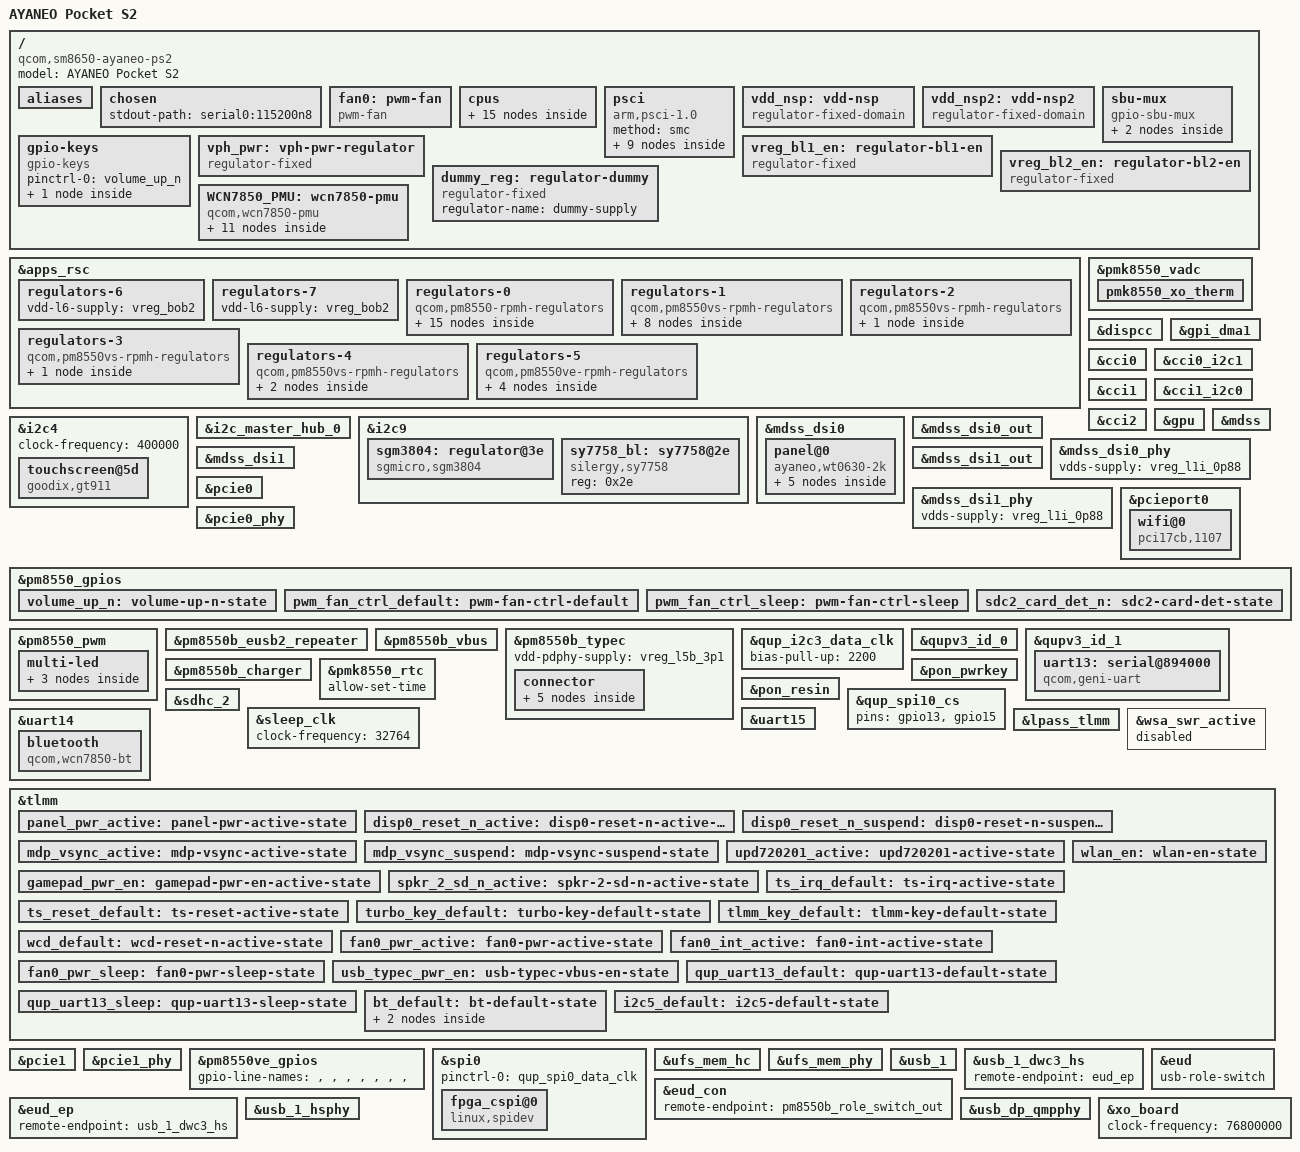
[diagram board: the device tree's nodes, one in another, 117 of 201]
/dts-v1/;

#include <dt-bindings/leds/common.h>
#include <dt-bindings/regulator/qcom,rpmh-regulator.h>
#include <dt-bindings/phy/phy.h>
#include "dt-bindings/usb/pd.h"
#include "sm8650.dtsi"
#include "pm8010.dtsi"
#include "pm8550.dtsi"
#include "pm8550b.dtsi"
#include "pm8550vs.dtsi"
#define PMK8550VE_SID 8
#include "pm8550ve.dtsi"
#include "pmk8550.dtsi"
#include "sm8650-el2.dtsi"

/ {
	model = "AYANEO Pocket S2";
	compatible = "qcom,sm8650-ayaneo-ps2", "qcom,sm8650";

	aliases {
		serial0 = &uart15;
		serial1 = &uart14;
		hsuart0 = &uart13;
	};

	chosen {
		stdout-path = "serial0:115200n8";
	};	

	fan0: pwm-fan {
		status = "okay";
		compatible = "pwm-fan";
		#cooling-cells = <2>;
		interrupt-parent = <&tlmm>;
		interrupts = <14 IRQ_TYPE_EDGE_FALLING>;
		pinctrl-names = "default", "sleep";
		pinctrl-0 = <&fan0_pwr_active>, <&pwm_fan_ctrl_default>, <&fan0_int_active>;
		pinctrl-1 = <&fan0_pwr_sleep>;
		pwms = <&pm8550_pwm 3 50000>;
		cooling-levels = <0 16 32 45 60 80 105 130 155 180 205 230 255>;
	};
	
	cpus {

		CPU0: cpu@0 {
			power-domains = <&CPU_PD0>;
			power-domain-names = "psci";
		};

		CPU1: cpu@100 {
			power-domains = <&CPU_PD1>;
			power-domain-names = "psci";
		};

		CPU2: cpu@200 {
			power-domains = <&CPU_PD2>;
			power-domain-names = "psci";
		};

		CPU3: cpu@300 {
			power-domains = <&CPU_PD3>;
			power-domain-names = "psci";
		};

		CPU4: cpu@400 {
			power-domains = <&CPU_PD4>;
			power-domain-names = "psci";
		};

		CPU5: cpu@500 {
			power-domains = <&CPU_PD5>;
			power-domain-names = "psci";
		};

		CPU6: cpu@600 {
			power-domains = <&CPU_PD6>;
			power-domain-names = "psci";
		};

		CPU7: cpu@700 {
			power-domains = <&CPU_PD7>;
			power-domain-names = "psci";
		};

		idle-states {
			entry-method = "psci";

			SILVER_CPU_SLEEP_0: cpu-sleep-0-0 {
				compatible = "arm,idle-state";
				idle-state-name = "silver-rail-power-collapse";
				arm,psci-suspend-param = <0x40000004>;
				entry-latency-us = <550>;
				exit-latency-us = <750>;
				min-residency-us = <6700>;
				local-timer-stop;
			};

			GOLD_CPU_SLEEP_0: cpu-sleep-1-0 {
				compatible = "arm,idle-state";
				idle-state-name = "gold-rail-power-collapse";
				arm,psci-suspend-param = <0x40000004>;
				entry-latency-us = <600>;
				exit-latency-us = <1300>;
				min-residency-us = <8136>;
				local-timer-stop;
			};

			GOLD_PLUS_CPU_SLEEP_0: cpu-sleep-2-0 {
				compatible = "arm,idle-state";
				idle-state-name = "gold-plus-rail-power-collapse";
				arm,psci-suspend-param = <0x40000004>;
				entry-latency-us = <500>;
				exit-latency-us = <1350>;
				min-residency-us = <7480>;
				local-timer-stop;
			};
		};

		domain-idle-states {
			CLUSTER_SLEEP_0: cluster-sleep-0 {
				compatible = "domain-idle-state";
				arm,psci-suspend-param = <0x41000044>;
				entry-latency-us = <750>;
				exit-latency-us = <2350>;
				min-residency-us = <9144>;
			};

			CLUSTER_SLEEP_1: cluster-sleep-1 {
				compatible = "domain-idle-state";
				arm,psci-suspend-param = <0x4100c344>;
				entry-latency-us = <2800>;
				exit-latency-us = <4400>;
				min-residency-us = <10150>;
			};
		};
	};

	psci {
		compatible = "arm,psci-1.0";
		method = "smc";

		CPU_PD0: power-domain-cpu0 {
			#power-domain-cells = <0>;
			power-domains = <&CLUSTER_PD>;
			domain-idle-states = <&SILVER_CPU_SLEEP_0>;
		};

		CPU_PD1: power-domain-cpu1 {
			#power-domain-cells = <0>;
			power-domains = <&CLUSTER_PD>;
			domain-idle-states = <&SILVER_CPU_SLEEP_0>;
		};

		CPU_PD2: power-domain-cpu2 {
			#power-domain-cells = <0>;
			power-domains = <&CLUSTER_PD>;
			domain-idle-states = <&SILVER_CPU_SLEEP_0>;
		};

		CPU_PD3: power-domain-cpu3 {
			#power-domain-cells = <0>;
			power-domains = <&CLUSTER_PD>;
			domain-idle-states = <&GOLD_CPU_SLEEP_0>;
		};

		CPU_PD4: power-domain-cpu4 {
			#power-domain-cells = <0>;
			power-domains = <&CLUSTER_PD>;
			domain-idle-states = <&GOLD_CPU_SLEEP_0>;
		};

		CPU_PD5: power-domain-cpu5 {
			#power-domain-cells = <0>;
			power-domains = <&CLUSTER_PD>;
			domain-idle-states = <&GOLD_CPU_SLEEP_0>;
		};

		CPU_PD6: power-domain-cpu6 {
			#power-domain-cells = <0>;
			power-domains = <&CLUSTER_PD>;
			domain-idle-states = <&GOLD_CPU_SLEEP_0>;
		};

		CPU_PD7: power-domain-cpu7 {
			#power-domain-cells = <0>;
			power-domains = <&CLUSTER_PD>;
			domain-idle-states = <&GOLD_PLUS_CPU_SLEEP_0>;
		};

		CLUSTER_PD: power-domain-cluster {
			#power-domain-cells = <0>;
			domain-idle-states = <&CLUSTER_SLEEP_0>,
					     <&CLUSTER_SLEEP_1>;
		};
	};

	vdd_nsp: vdd-nsp {
		compatible = "regulator-fixed-domain";
		power-domains = <&rpmhpd RPMHPD_NSP>;
		required-opps = <&rpmhpd_opp_nom>;
		regulator-name = "NSP";
		regulator-always-on;
	};

	vdd_nsp2: vdd-nsp2 {
		compatible = "regulator-fixed-domain";
		power-domains = <&rpmhpd RPMHPD_NSP2>;
		required-opps = <&rpmhpd_opp_nom>;
		regulator-name = "NSP2";
		regulator-always-on;
	};

	sbu-mux {
		compatible = "gpio-sbu-mux";

		enable-gpios = <&tlmm 86 GPIO_ACTIVE_LOW>;
		select-gpios = <&tlmm 82 GPIO_ACTIVE_HIGH>;

		mode-switch;
		orientation-switch;

		port {
			sbu_mux_in: endpoint {
				remote-endpoint = <&tcpm_sbu_out>;
			};
		};

		// XXX: needs VREG_L05B_3P1, VREG_BOB2
	};

	gpio-keys {
		compatible = "gpio-keys";

		pinctrl-0 = <&volume_up_n>;
		pinctrl-names = "default";

		key-volume-up {
			label = "Volume Up";
			linux,code = <KEY_VOLUMEUP>;
			gpios = <&pm8550_gpios 6 GPIO_ACTIVE_LOW>;
			debounce-interval = <15>;
			linux,can-disable;
			//wakeup-source;
		};
	};

	vph_pwr: vph-pwr-regulator {
		compatible = "regulator-fixed";

		regulator-name = "vph_pwr";
		regulator-min-microvolt = <3700000>;
		regulator-max-microvolt = <3700000>;

		regulator-always-on;
		regulator-boot-on;
	};

	vreg_bl1_en: regulator-bl1-en {
		compatible = "regulator-fixed";
		regulator-name = "vreg_bl1_en";
		gpio = <&tlmm 163 GPIO_ACTIVE_HIGH>;
		enable-active-high;
		regulator-always-on;
	};

	vreg_bl2_en: regulator-bl2-en {
		compatible = "regulator-fixed";
		regulator-name = "vreg_bl2_en";
		gpio = <&tlmm 164 GPIO_ACTIVE_HIGH>;
		enable-active-high;
		regulator-always-on;
	};

	dummy_reg: regulator-dummy {
		compatible = "regulator-fixed";
		regulator-name = "dummy-supply";
	};

	WCN7850_PMU: wcn7850-pmu {
		compatible = "qcom,wcn7850-pmu";

		pinctrl-names = "default";
		pinctrl-0 = <&wlan_en>, <&bt_default>;

		wlan-enable-gpios = <&tlmm 16 GPIO_ACTIVE_HIGH>;
		bt-enable-gpios = <&tlmm 17 GPIO_ACTIVE_HIGH>;

		vdd-supply = <&vreg_s4i_0p85>;
		vddio-supply = <&vreg_l15b_1p8>;
		vddio1p2-supply = <&vreg_l3c_1p2>;
		vddaon-supply = <&vreg_s2c_0p8>;
		vdddig-supply = <&vreg_s3c_0p9>;
		vddrfa1p2-supply = <&vreg_s1c_1p2>;
		vddrfa1p8-supply = <&vreg_s6c_1p8>;

		clocks = <&rpmhcc RPMH_RF_CLK1>;

		regulators {
			vreg_pmu_rfa_cmn: ldo0 {
				regulator-name = "vreg_pmu_rfa_cmn";
			};

			vreg_pmu_aon_0p59: ldo1 {
				regulator-name = "vreg_pmu_aon_0p59";
			};

			vreg_pmu_wlcx_0p8: ldo2 {
				regulator-name = "vreg_pmu_wlcx_0p8";
			};

			vreg_pmu_wlmx_0p85: ldo3 {
				regulator-name = "vreg_pmu_wlmx_0p85";
			};

			vreg_pmu_btcmx_0p85: ldo4 {
				regulator-name = "vreg_pmu_btcmx_0p85";
			};

			vreg_pmu_rfa_0p8: ldo5 {
				regulator-name = "vreg_pmu_rfa_0p8";
			};

			vreg_pmu_rfa_1p2: ldo6 {
				regulator-name = "vreg_pmu_rfa_1p2";
			};

			vreg_pmu_rfa_1p8: ldo7 {
				regulator-name = "vreg_pmu_rfa_1p8";
			};

			vreg_pmu_pcie_0p9: ldo8 {
				regulator-name = "vreg_pmu_pcie_0p9";
			};

			vreg_pmu_pcie_1p8: ldo9 {
				regulator-name = "vreg_pmu_pcie_1p8";
			};
		};
	};


};


&apps_rsc {
    regulators-6 {
        vdd-l6-supply = <&vreg_bob2>;
    };
    regulators-7 {
        vdd-l6-supply = <&vreg_bob2>;
    };
};

&pmk8550_vadc {
	// NOTE TODO REVISIT - There is some chance to lower interrupt usage slightly if these are converted to thermal zones and qcom,adc-tm-type is set appropriately..

	// NOTE Setting qcom,adc-tm-type errors out driver and blocks all channels with obscure error. Need Thermal Zone setup to match.
	pmk8550_xo_therm {
		reg = <PMK8550_ADC5_GEN3_AMUX_THM1_XO_THERM_100K_PU(0)>;
		label = "pmk8550_xo_therm";
		qcom,ratiometric;
		qcom,hw-settle-time = <200>;
		qcom,pre-scaling = <1 1>;
	};



};

&apps_rsc {
	regulators-0 {
		compatible = "qcom,pm8550-rpmh-regulators";

		vdd-bob1-supply = <&vph_pwr>;
		vdd-bob2-supply = <&vph_pwr>;
		vdd-l1-l4-l10-supply = <&vreg_s6c_1p8>;
		vdd-l2-l13-l14-supply = <&vreg_bob1>;
		vdd-l3-supply = <&vreg_s1c_1p2>;
		vdd-l5-l16-supply = <&vreg_bob1>;
		vdd-l6-l7-supply = <&vreg_bob1>;
		vdd-l8-l9-supply = <&vreg_bob1>;
		vdd-l11-supply = <&vreg_s1c_1p2>;
		vdd-l12-supply = <&vreg_s6c_1p8>;
		vdd-l15-supply = <&vreg_s6c_1p8>;
		vdd-l17-supply = <&vreg_bob2>;

		qcom,pmic-id = "b";

		vreg_bob1: bob1 {
			regulator-name = "vreg_bob1";
			regulator-min-microvolt = <3296000>; // note: min is 3008000, init is 3296000
			regulator-max-microvolt = <3960000>;
			regulator-initial-mode = <RPMH_REGULATOR_MODE_HPM>;
		};

		vreg_bob2: bob2 {
			regulator-name = "vreg_bob2";
			regulator-min-microvolt = <2720000>; // note: min is 2704000, init is 2720000
			regulator-max-microvolt = <3008000>;
			regulator-initial-mode = <RPMH_REGULATOR_MODE_HPM>;

			regulator-always-on; // XXX USB HS, SBU MUX
		};

		vreg_l2b_3p0: ldo2 {
			regulator-name = "vreg_l2b_3p0";
			regulator-min-microvolt = <3008000>;
			regulator-max-microvolt = <3008000>;
			regulator-initial-mode = <RPMH_REGULATOR_MODE_HPM>;
			regulator-allow-set-load;
			regulator-allowed-modes = <RPMH_REGULATOR_MODE_LPM
						   RPMH_REGULATOR_MODE_HPM>;
		};

		vreg_l5b_3p1: ldo5 {
			regulator-name = "vreg_l5b_3p1";
			regulator-min-microvolt = <3104000>;
			regulator-max-microvolt = <3104000>;
			regulator-initial-mode = <RPMH_REGULATOR_MODE_HPM>;
			regulator-allow-set-load;
			regulator-allowed-modes = <RPMH_REGULATOR_MODE_LPM
						   RPMH_REGULATOR_MODE_HPM>;
			regulator-always-on; // XXX SBU MUX
		};

		vreg_l6b_1p8: ldo6 {
			regulator-name = "vreg_l6b_1p8";
			regulator-min-microvolt = <1800000>;
			regulator-max-microvolt = <3008000>;
			regulator-initial-mode = <RPMH_REGULATOR_MODE_HPM>;
			regulator-allow-set-load;
			regulator-allowed-modes = <RPMH_REGULATOR_MODE_LPM
						   RPMH_REGULATOR_MODE_HPM>;
		};

		vreg_l7b_1p8: ldo7 {
			regulator-name = "vreg_l7b_1p8";
			regulator-min-microvolt = <1800000>;
			regulator-max-microvolt = <3008000>;
			regulator-initial-mode = <RPMH_REGULATOR_MODE_HPM>;
		};
		
		vreg_l8b_1p8: ldo8 {
			regulator-name = "vreg_l8b_1p8";
			regulator-min-microvolt = <1800000>;
			regulator-max-microvolt = <3008000>;
			regulator-initial-mode = <RPMH_REGULATOR_MODE_HPM>;
			regulator-allow-set-load;
			regulator-allowed-modes = <RPMH_REGULATOR_MODE_LPM
						   RPMH_REGULATOR_MODE_HPM>;
		};

		vreg_l9b_2p9: ldo9 {
			regulator-name = "vreg_l9b_2p9";
			regulator-min-microvolt = <2960000>;
			regulator-max-microvolt = <3008000>;
			regulator-initial-mode = <RPMH_REGULATOR_MODE_HPM>;
			regulator-allow-set-load;
			regulator-allowed-modes = <RPMH_REGULATOR_MODE_LPM
						   RPMH_REGULATOR_MODE_HPM>;
		};


		vreg_l11b_1p2: ldo11 {
			regulator-name = "vreg_l11b_1p2";
			regulator-min-microvolt = <1200000>;
			regulator-max-microvolt = <1504000>;
			regulator-initial-mode = <RPMH_REGULATOR_MODE_HPM>;
			regulator-allow-set-load;
			regulator-allowed-modes = <RPMH_REGULATOR_MODE_LPM
						   RPMH_REGULATOR_MODE_HPM>;
		};

		vreg_l12b_1p8: ldo12 {
			regulator-name = "vreg_l12b_1p8";
			regulator-min-microvolt = <1800000>;
			regulator-max-microvolt = <1800000>;
			regulator-initial-mode = <RPMH_REGULATOR_MODE_HPM>;
			regulator-allow-set-load;
			regulator-allowed-modes = <RPMH_REGULATOR_MODE_LPM
						   RPMH_REGULATOR_MODE_HPM>;
		};

		vreg_l13b_3p0: ldo13 {
			regulator-name = "vreg_l13b_3p0";
			regulator-min-microvolt = <3000000>;
			regulator-max-microvolt = <3000000>;
			regulator-initial-mode = <RPMH_REGULATOR_MODE_HPM>;
			regulator-allow-set-load;
			regulator-allowed-modes = <RPMH_REGULATOR_MODE_LPM
						   RPMH_REGULATOR_MODE_HPM>;
		};
	
		vreg_l14b_3p2: ldo14 {
			regulator-name = "vreg_l14b_3p2";
			regulator-min-microvolt = <3200000>;
			regulator-max-microvolt = <3200000>;
			regulator-initial-mode = <RPMH_REGULATOR_MODE_HPM>;
			regulator-allow-set-load;
			regulator-allowed-modes = <RPMH_REGULATOR_MODE_LPM
						   RPMH_REGULATOR_MODE_HPM>;
		};
	
		vreg_l15b_1p8: ldo15 {
			regulator-name = "vreg_l15b_1p8";
			regulator-min-microvolt = <1800000>;
			regulator-max-microvolt = <1800000>;
			regulator-initial-mode = <RPMH_REGULATOR_MODE_HPM>;
			regulator-allow-set-load;
			regulator-allowed-modes = <RPMH_REGULATOR_MODE_LPM
						   RPMH_REGULATOR_MODE_HPM>;
		};

		vreg_l16b_2p8: ldo16 {
			regulator-name = "vreg_l16b_2p8";
			regulator-min-microvolt = <2800000>;
			regulator-max-microvolt = <2800000>;
			regulator-initial-mode = <RPMH_REGULATOR_MODE_HPM>;
			regulator-allow-set-load;
			regulator-allowed-modes = <RPMH_REGULATOR_MODE_LPM
						   RPMH_REGULATOR_MODE_HPM>;
		};
		
		vreg_l17b_2p5: ldo17 {
			regulator-name = "vreg_l17b_2p5";
			regulator-min-microvolt = <2504000>;
			regulator-max-microvolt = <2504000>;
			regulator-initial-mode = <RPMH_REGULATOR_MODE_HPM>;
			regulator-allow-set-load;
			regulator-allowed-modes = <RPMH_REGULATOR_MODE_LPM
						   RPMH_REGULATOR_MODE_HPM>;
		};
	};

	regulators-1 {
		compatible = "qcom,pm8550vs-rpmh-regulators";

		vdd-l1-supply = <&vreg_s1c_1p2>;
		vdd-l2-supply = <&vreg_s1c_1p2>;
		vdd-l3-supply = <&vreg_s1c_1p2>;
		vdd-s1-supply = <&vph_pwr>;
		vdd-s2-supply = <&vph_pwr>;
		vdd-s3-supply = <&vph_pwr>;
		vdd-s4-supply = <&vph_pwr>;
		vdd-s5-supply = <&vph_pwr>;
		vdd-s6-supply = <&vph_pwr>;

		qcom,pmic-id = "c";

		vreg_s1c_1p2: smps1 {
			regulator-name = "vreg_s1c_1p2";
			regulator-min-microvolt = <1224000>;
			regulator-max-microvolt = <1348000>;
			// init 1256000
			regulator-initial-mode = <RPMH_REGULATOR_MODE_HPM>;

			regulator-always-on; // USB, UFS?
		};

		vreg_s2c_0p8: smps2 {
			regulator-name = "vreg_s2c_0p8";
			regulator-min-microvolt = <852000>;
			regulator-max-microvolt = <1036000>;
			// init 852000
			regulator-initial-mode = <RPMH_REGULATOR_MODE_HPM>;
		};

		vreg_s3c_0p9: smps3 {
			regulator-name = "vreg_s3c_0p9";
			regulator-min-microvolt = <904000>;
			regulator-max-microvolt = <1064000>;
			// init 976000
			regulator-initial-mode = <RPMH_REGULATOR_MODE_HPM>;
		};

		vreg_s4c_1p2: smps4 {
			regulator-name = "vreg_s4c_1p2";
			regulator-min-microvolt = <1200000>;
			regulator-max-microvolt = <1280000>;
			// init 1224000
			regulator-initial-mode = <RPMH_REGULATOR_MODE_HPM>;
		};

		vreg_s5c_0p7: smps5 {
			regulator-name = "vreg_s5c_0p7";
			regulator-min-microvolt = <752000>;
			regulator-max-microvolt = <900000>;
			// init 752000
			regulator-initial-mode = <RPMH_REGULATOR_MODE_HPM>;
		};

		vreg_s6c_1p8: smps6 {
			regulator-name = "vreg_s6c_1p8";
			regulator-min-microvolt = <1856000>;
			regulator-max-microvolt = <2000000>;
			// init 1856000
			regulator-initial-mode = <RPMH_REGULATOR_MODE_HPM>;
		};

		vreg_l1c_1p2: ldo1 {
			regulator-name = "vreg_l1c_1p2";
			regulator-min-microvolt = <1200000>; // note: min 1100000
			regulator-max-microvolt = <1200000>;
			regulator-initial-mode = <RPMH_REGULATOR_MODE_HPM>;
			regulator-allow-set-load;
			regulator-allowed-modes = <RPMH_REGULATOR_MODE_LPM
						   RPMH_REGULATOR_MODE_HPM>;
		};

		vreg_l3c_1p2: ldo3 {
			regulator-name = "vreg_l3c_1p2";
			regulator-min-microvolt = <1200000>;
			regulator-max-microvolt = <1200000>;
			regulator-initial-mode = <RPMH_REGULATOR_MODE_HPM>;
			regulator-allow-set-load;
			regulator-allowed-modes = <RPMH_REGULATOR_MODE_LPM
						   RPMH_REGULATOR_MODE_HPM>;
		};
	};

	regulators-2 {
		compatible = "qcom,pm8550vs-rpmh-regulators";
		qcom,pmic-id = "d";

		vdd-l1-supply = <&vreg_s3c_0p9>;

		vreg_l1d_0p9: ldo1 {
			regulator-name = "vreg_l1d_0p9";
			regulator-min-microvolt = <912000>; // note: min 880000
			regulator-max-microvolt = <920000>;
			regulator-initial-mode = <RPMH_REGULATOR_MODE_HPM>;
			regulator-allow-set-load;
			regulator-allowed-modes = <RPMH_REGULATOR_MODE_LPM
						   RPMH_REGULATOR_MODE_HPM>;
		};
	};

	regulators-3 {
		compatible = "qcom,pm8550vs-rpmh-regulators";

		vdd-l3-supply = <&vreg_s3c_0p9>;

		qcom,pmic-id = "e";

		vreg_l3e_0p9: ldo3 {
			regulator-name = "vreg_l3e_0p9";
			regulator-min-microvolt = <880000>;
			regulator-max-microvolt = <920000>;
			regulator-initial-mode = <RPMH_REGULATOR_MODE_HPM>;
			regulator-allow-set-load;
			regulator-allowed-modes = <RPMH_REGULATOR_MODE_LPM
						   RPMH_REGULATOR_MODE_HPM>;
		};
	};

	regulators-4 {
		compatible = "qcom,pm8550vs-rpmh-regulators";

		vdd-l1-supply = <&vreg_s3c_0p9>;
		vdd-l3-supply = <&vreg_s3c_0p9>;

		qcom,pmic-id = "g";

		vreg_l1g_0p91: ldo1 {
			regulator-name = "vreg_l1g_0p91";
			regulator-min-microvolt = <912000>;
			regulator-max-microvolt = <920000>;
			regulator-initial-mode = <RPMH_REGULATOR_MODE_HPM>;
			regulator-allow-set-load;
			regulator-allowed-modes = <RPMH_REGULATOR_MODE_LPM
						   RPMH_REGULATOR_MODE_HPM>;
		};

		vreg_l3g_0p91: ldo3 {
			regulator-name = "vreg_l3g_0p91";
			regulator-min-microvolt = <880000>;
			regulator-max-microvolt = <912000>;
			regulator-initial-mode = <RPMH_REGULATOR_MODE_HPM>;
			regulator-allow-set-load;
			regulator-allowed-modes = <RPMH_REGULATOR_MODE_LPM
						   RPMH_REGULATOR_MODE_HPM>;
		};
	};
	
	regulators-5 {
		compatible = "qcom,pm8550ve-rpmh-regulators";

		vdd-l1-supply = <&vreg_s3c_0p9>;
		vdd-l2-supply = <&vreg_s3c_0p9>;
		vdd-l3-supply = <&vreg_s1c_1p2>;
		vdd-s4-supply = <&vph_pwr>;

		qcom,pmic-id = "i";

		vreg_s4i_0p85: smps4 {
			regulator-name = "vreg_s4i_0p85";
			regulator-min-microvolt = <852000>;
			regulator-max-microvolt = <1004000>;
			// init 852000
			regulator-initial-mode = <RPMH_REGULATOR_MODE_HPM>;
		};

		vreg_l1i_0p88: ldo1 {
			regulator-name = "vreg_l1i_0p88";
			regulator-min-microvolt = <880000>;
			regulator-max-microvolt = <912000>;
			regulator-initial-mode = <RPMH_REGULATOR_MODE_HPM>;
			regulator-allow-set-load;
			regulator-allowed-modes = <RPMH_REGULATOR_MODE_LPM
						   RPMH_REGULATOR_MODE_HPM>;
		};

		vreg_l2i_0p88: ldo2 {
			regulator-name = "vreg_l2i_0p88";
			regulator-min-microvolt = <880000>;
			regulator-max-microvolt = <912000>;
			regulator-initial-mode = <RPMH_REGULATOR_MODE_HPM>;
			regulator-allow-set-load;
			regulator-allowed-modes = <RPMH_REGULATOR_MODE_LPM
						   RPMH_REGULATOR_MODE_HPM>;
		};

		vreg_l3i_1p2: ldo3 {
			regulator-name = "vreg_l3i_0p91";
			regulator-min-microvolt = <1200000>;
			regulator-max-microvolt = <1200000>;
			regulator-initial-mode = <RPMH_REGULATOR_MODE_HPM>;
			regulator-allow-set-load;
			regulator-allowed-modes = <RPMH_REGULATOR_MODE_LPM
						   RPMH_REGULATOR_MODE_HPM>;
		};
	};

};


&dispcc {
	status = "okay";
};

&gpi_dma1 {
	status = "okay";
};



&cci0 {
	status = "okay";
};



&cci0_i2c1 {

};

&cci1 {
	pinctrl-0 = <&cci1_0_default>;
	pinctrl-1 = <&cci1_0_sleep>;
	status = "okay";
};

&cci1_i2c0 {

};

&cci2 {
	status = "okay";
};


&i2c4 {
	status = "okay";
	clock-frequency = <400000>;

	touchscreen@5d {
		reg = <0x5d>;
		status = "okay";
		compatible = "goodix,gt911";

		interrupt-parent = <&tlmm>;
		interrupts = <162 IRQ_TYPE_EDGE_FALLING>;

		reset-gpios = <&tlmm 161 GPIO_ACTIVE_HIGH>;
		VDDIO-supply = <&vreg_l14b_3p2>;
		AVDD28-supply = <&vreg_l14b_3p2>;

		touchscreen-size-x = <1440>;
		touchscreen-size-y = <2560>;

		pinctrl-names = "default";
		pinctrl-0 = <&ts_reset_default>, <&ts_irq_default>, <&usb_typec_pwr_en>;
	};
};

&gpu {
	status = "okay";
};

// Master Hub required for Hub 7 and 8
&i2c_master_hub_0 {
	status = "okay";
};

&mdss {
	status = "okay";
};


&i2c9 {
	status = "okay";

	/* Screen power */
	sgm3804: regulator@3e {
		compatible = "sgmicro,sgm3804";
		reg = <0x3e>;
		pinctrl-names = "default";
		pinctrl-0 = <&panel_pwr_active>;
		regulator-name = "panel-avdd";
		regulator-min-microvolt = <5000000>;
		regulator-max-microvolt = <5000000>;
		reset-gpios = <&tlmm 59 GPIO_ACTIVE_HIGH>, <&tlmm 58 GPIO_ACTIVE_HIGH>;
		status = "okay";
	};

	/* Backlight */
	sy7758_bl: sy7758@2e {
		compatible = "silergy,sy7758";
		reg = <0x2e>;
		status = "okay";
	};
};



&mdss_dsi0 {
	status = "okay";
	qcom,master-dsi;
	qcom,dual-dsi-mode;
	qcom,sync-dual-dsi;
	vdda-supply = <&vreg_l3i_1p2>;
	
	panel@0 {
		status = "okay";
		compatible = "ayaneo,wt0630-2k";
		reg = <0>;
		pinctrl-names = "default", "sleep";
		pinctrl-0 = <&disp0_reset_n_active>;
		pinctrl-1 = <&disp0_reset_n_suspend>;

		vddio-supply = <&vreg_l12b_1p8>;
		vci-supply = <&vreg_l13b_3p0>;
		vdd-supply = <&vreg_l11b_1p2>;
		avdd-supply = <&sgm3804>;

		reset-gpios = <&tlmm 133 GPIO_ACTIVE_LOW>;
		backlight = <&sy7758_bl>;

		ports {
			#address-cells = <1>;
			#size-cells = <0>;

			port@0 {
				reg = <0>;
				panel0_in_0: endpoint {
					remote-endpoint = <&mdss_dsi0_out>;
				};
			};

			port@1{
				reg = <1>;
				panel0_in_1: endpoint {
					remote-endpoint = <&mdss_dsi1_out>;
				};
			};
		};
	};
};

&mdss_dsi0_out {
	remote-endpoint = <&panel0_in_0>;
	data-lanes = <0 1 2 3>;
};

&mdss_dsi0_phy {
	vdds-supply = <&vreg_l1i_0p88>;

	status = "okay";
};

&mdss_dsi1 {
	vdda-supply = <&vreg_l3i_1p2>;
	qcom,dual-dsi-mode;
	qcom,sync-dual-dsi;
	assigned-clock-parents = <&mdss_dsi0_phy DSI_BYTE_PLL_CLK>, <&mdss_dsi0_phy DSI_PIXEL_PLL_CLK>;
	status = "okay";
};

&mdss_dsi1_out {
	remote-endpoint = <&panel0_in_1>;
	data-lanes = <0 1 2 3>;
};

&mdss_dsi1_phy {
	vdds-supply = <&vreg_l1i_0p88>;

	status = "okay";
};

#if 0
&mdss_dp0 {
	status = "okay";
};

&mdss_dp0_out {
	data-lanes = <0 1>;
};
#endif

&pcie0 {
	wake-gpios = <&tlmm 96 GPIO_ACTIVE_HIGH>;
	perst-gpios = <&tlmm 94 GPIO_ACTIVE_LOW>;

	pinctrl-0 = <&pcie0_default_state>;
	pinctrl-names = "default";

	status = "okay";
};

&pcieport0 {
	wifi@0 {
		compatible = "pci17cb,1107";
		reg = <0x10000 0x0 0x0 0x0 0x0>;

		vddrfacmn-supply = <&vreg_pmu_rfa_cmn>;
		vddaon-supply = <&vreg_pmu_aon_0p59>;
		vddwlcx-supply = <&vreg_pmu_wlcx_0p8>;
		vddwlmx-supply = <&vreg_pmu_wlmx_0p85>;
		vddrfa0p8-supply = <&vreg_pmu_rfa_0p8>;
		vddrfa1p2-supply = <&vreg_pmu_rfa_1p2>;
		vddrfa1p8-supply = <&vreg_pmu_rfa_1p8>;
		vddpcie0p9-supply = <&vreg_pmu_pcie_0p9>;
		vddpcie1p8-supply = <&vreg_pmu_pcie_1p8>;

		qcom,default-bdf = "board_77.bin";
	};
};

&pcie0_phy {
	vdda-phy-supply = <&vreg_l1i_0p88>;
	vdda-pll-supply = <&vreg_l3i_1p2>;

	status = "okay";
};

&pm8550_gpios {
	volume_up_n: volume-up-n-state {
		pins = "gpio6";
		function = "normal";
		bias-pull-up;
		input-enable;
		power-source = <1>;
	};

	pwm_fan_ctrl_default: pwm-fan-ctrl-default {
		pins = "gpio9";
		function = "func1";
		output-low;
		bias-disable;
		power-source = <0>;
		qcom,drive-strength = <3>; /* PMIC_GPIO_STRENGTH_LOW */
	};

	pwm_fan_ctrl_sleep: pwm-fan-ctrl-sleep {
		pins = "gpio9";
		function = "func0";
		output-high;
		bias-disable;
		power-source = <0>;
		qcom,drive-strength = <3>; /* PMIC_GPIO_STRENGTH_LOW */
	};
	
	sdc2_card_det_n: sdc2-card-det-state {
		pins = "gpio12";
		function = "normal";
		bias-pull-up;
		input-enable;
		output-disable;
		power-source = <1>; /* 1.8 V */
	};


};

&pm8550_pwm {
	status = "okay";

	multi-led {
		color = <LED_COLOR_ID_RGB>;
		function = LED_FUNCTION_STATUS;

		#address-cells = <1>;
		#size-cells = <0>;

		led@1 {
			reg = <1>;
			color = <LED_COLOR_ID_RED>;
		};

		led@2 {
			reg = <2>;
			color = <LED_COLOR_ID_GREEN>;
		};

		led@3 {
			reg = <3>;
			color = <LED_COLOR_ID_BLUE>;
		};
	};
};

&pm8550b_eusb2_repeater {
	vdd18-supply = <&vreg_l15b_1p8>;
	vdd3-supply = <&vreg_l5b_3p1>;
};

&pm8550b_vbus {
	status = "okay";
};

&pm8550b_typec {
	status = "okay";

	vdd-pdphy-supply = <&vreg_l5b_3p1>;

	connector {
		power-role = "dual";
		data-role = "dual";
		try-power-role = "sink";
		
		source-pdos = <PDO_FIXED(5000, 3000, PDO_FIXED_DUAL_ROLE | PDO_FIXED_DATA_SWAP | PDO_FIXED_USB_COMM)>;
		
		//sink-pdos needs to have 5000mV entry first otherwise will not probe
		sink-pdos = <PDO_FIXED(5000, 3000, PDO_FIXED_DUAL_ROLE | PDO_FIXED_DATA_SWAP | PDO_FIXED_USB_COMM)>,
                    <PDO_FIXED(9000, 3000, PDO_FIXED_DUAL_ROLE | PDO_FIXED_DATA_SWAP | PDO_FIXED_USB_COMM)>,
                    <PDO_FIXED(12000, 3000, PDO_FIXED_DUAL_ROLE | PDO_FIXED_DATA_SWAP | PDO_FIXED_USB_COMM)>,
                    <PDO_FIXED(15000, 3000, PDO_FIXED_DUAL_ROLE | PDO_FIXED_DATA_SWAP | PDO_FIXED_USB_COMM)>;

		op-sink-microwatt = <15000000>;

		ports {
			#address-cells = <1>;
			#size-cells = <0>;

			port@0 {
				reg = <0>;

				pm8550b_role_switch_out: endpoint {
					remote-endpoint = <&eud_con>;
				};
			};

			port@1 {
				reg = <1>;

				tcpm_sbu_out: endpoint {
					remote-endpoint = <&sbu_mux_in>;
				};
			};


		};
	};

};

&qup_i2c3_data_clk {
	/* Use internal I2C pull-up */
	bias-pull-up = <2200>;
};

&qupv3_id_0 {
	status = "okay";
};

&qupv3_id_1 {
	status = "okay";
	
	/* AYANEO Controller serial interface */
	uart13: serial@894000 {
		compatible = "qcom,geni-uart";
		reg = <0 0x00894000 0 0x4000>;
		interrupts = <GIC_SPI 587 IRQ_TYPE_LEVEL_HIGH 0>;
		clocks = <&gcc GCC_QUPV3_WRAP2_S5_CLK>;
		clock-names = "se";
		interconnects = <&clk_virt MASTER_QUP_CORE_2 QCOM_ICC_TAG_ALWAYS
					&clk_virt SLAVE_QUP_CORE_2 QCOM_ICC_TAG_ALWAYS>,
					<&gem_noc MASTER_APPSS_PROC QCOM_ICC_TAG_ACTIVE_ONLY
					&config_noc SLAVE_QUP_2 QCOM_ICC_TAG_ACTIVE_ONLY>;
		interconnect-names = "qup-core",
						"qup-config";
		power-domains = <&rpmhpd RPMHPD_CX>;
		operating-points-v2 = <&qup_opp_table_100mhz>;
		pinctrl-0 = <&qup_uart13_default>;
		pinctrl-names = "default";
		status = "okay";
	};
};

&pm8550b_charger {
	status = "okay";
	qph1-charge-current-max = <1200000>;
	qph2-charge-current-max = <2700000>;
};

&pmk8550_rtc {
	status = "okay";
	allow-set-time;
};

&pon_pwrkey {
	status = "okay";
};

&pon_resin {
	linux,code = <KEY_VOLUMEDOWN>;
	disable-wake-source;
	status = "okay";
};

&qup_spi10_cs {
	pins = "gpio13", "gpio15";
};

&qupv3_id_0 {
	status = "okay";
};

&qupv3_id_1 {
	status = "okay";
};



&sdhc_2 {
	cd-gpios = <&pm8550_gpios 12 GPIO_ACTIVE_LOW>;

	vmmc-supply = <&vreg_l9b_2p9>;
	vqmmc-supply = <&vreg_l8b_1p8>; // actually level shifter
	bus-width = <4>;
	no-sdio;
	no-mmc;

	pinctrl-0 = <&sdc2_default>, <&sdc2_card_det_n>;
	pinctrl-1 = <&sdc2_sleep>, <&sdc2_card_det_n>;
	pinctrl-names = "default", "sleep";

	status = "okay";
};

&sleep_clk {
	clock-frequency = <32764>;
};


&uart14 {
	status = "okay";

	bluetooth {
		compatible = "qcom,wcn7850-bt";

		vddrfacmn-supply = <&vreg_pmu_rfa_cmn>;
		vddaon-supply = <&vreg_pmu_aon_0p59>;
		vddwlcx-supply = <&vreg_pmu_wlcx_0p8>;
		vddwlmx-supply = <&vreg_pmu_wlmx_0p85>;
		vddrfa0p8-supply = <&vreg_pmu_rfa_0p8>;
		vddrfa1p2-supply = <&vreg_pmu_rfa_1p2>;
		vddrfa1p8-supply = <&vreg_pmu_rfa_1p8>;

		max-speed = <3200000>;
	};
};


&uart15 {
	status = "okay";
};



&lpass_tlmm {
	status = "okay";
};

// Disable Soundwire
&wsa_swr_active {
	status = "disabled";
};

&tlmm {
	// TODO verify reserved pins for 8650
	// qcom,gpios-reserved = <36 37 38 39>;
	gpio-line-names =
		// GPIO000 - GPIO015
		"",  "",  "",  "",  "",  "",  "",  "fpga_rst",  "",  "",  "",  "nrf_time_sync",  "",  "",  "",  "",
		// GPIO016 - GPIO031
		"",  "",  "",  "",  "",  "",  "",  "",  "",  "",  "",  "",  "",  "",  "",  "",
		// GPIO032 - GPIO047
		"",  "",  "",  "fpga_spi_cs",  "",  "",  "",  "fpga_crst",  "",  "",  "",  "",  "",  "",  "",  "",
		// GPIO048 - GPIO063
		"",  "",  "nrf_swdio",  "nrf_swclk",  "",  "",  "",  "",  "fpga_cam0_strobe",  "fpga_cam1_strobe",  "",  "",  "",  "",  "",  "",
		// GPIO064 - GPIO079
		"",  "",  "",  "",  "",  "",  "",  "",  "",  "",  "",  "",  "",  "",  "",  "",
		// GPIO080 - GPIO095
		"",  "",  "",  "",  "",  "",  "",  "",  "",  "",  "",  "",  "",  "",  "",  "",
		// GPIO096 - GPIO111
		"",  "",  "",  "",  "",  "",  "",  "",  "",  "",  "",  "",  "",  "",  "fpga_cam1_frame_sync",  "",
		// GPIO112 - GPIO127
		"",  "",  "",  "",  "",  "",  "",  "",  "",  "",  "",  "",  "fpga_cam0_frame_sync",  "",  "",  "",
		// GPIO128 - GPIO143
		"",  "",  "",  "",  "",  "",  "",  "",  "",  "",  "",  "",  "",  "",  "",  "",
		// GPIO144 - GPIO159
		"",  "",  "",  "",  "",  "",  "",  "",  "",  "",  "",  "fpga_cdone",  "",  "",  "fpga_cready",  "",
		// GPIO160 - GPIO175
		"",  "",  "te2_left",  "",  "nrf_reset",  "",  "",  "",  "",  "",  "",  "",  "",  "",  "",  "",
		// GPIO176 - GPIO189
		"",  "",  "te2_right",  "",  "", "", "", "", "", "", "", "", "", "";
};


&tlmm {
	status = "okay";
	
	panel_pwr_active: panel-pwr-active-state {
		pins = "gpio58", "gpio59", "gpio164", "gpio163"; 
		   //vreg_bl1_en and vreg_bl2_en added to enable panel power
		function = "gpio";
		drive-strength = <8>;
		bias-pull-up;
		output-high;
	};

	disp0_reset_n_active: disp0-reset-n-active-state {
		pins = "gpio133";
		function = "gpio";
		drive-strength = <8>;
		bias-disable;
	};

	disp0_reset_n_suspend: disp0-reset-n-suspend-state {
		pins = "gpio133";
		function = "gpio";
		drive-strength = <2>;
		bias-pull-down;
	};

	mdp_vsync_active: mdp-vsync-active-state {
		pins = "gpio86";
		function = "mdp_vsync";
		drive-strength = <2>;
		bias-pull-down;
	};

	mdp_vsync_suspend: mdp-vsync-suspend-state {
		pins = "gpio86";
		function = "mdp_vsync";
		drive-strength = <2>;
		bias-pull-down;
	};

	upd720201_active: upd720201-active-state {
		pins = "gpio121",  "gpio122", "gpio123";
		function = "gpio";
		drive-strength = <2>;
		bias-pull-up;
		output-high;
	};

	gamepad_pwr_en: gamepad-pwr-en-active-state {
		pins = "gpio28";
		function = "gpio";
		drive-strength = <2>;
		bias-disable;
		output-high;
	};

	spkr_2_sd_n_active: spkr-2-sd-n-active-state {
		pins = "gpio77";
		function = "gpio";
		drive-strength = <16>;
		bias-disable;
		output-low;
	};

	ts_irq_default: ts-irq-active-state {
		pins = "gpio162";
		function = "gpio";
		drive-strength = <8>;
		bias-disable;
		input-enable;
	};

	ts_reset_default: ts-reset-active-state {
		pins = "gpio161";
		function = "gpio";
		drive-strength = <8>;
		input-enable;
		bias-pull-down;
	};

	turbo_key_default: turbo-key-default-state {
		pins = "gpio78", "gpio79", "gpio82";
		function = "gpio";
		drive-strength = <2>;
		input-enable;
		bias-pull-up;
	};

	tlmm_key_default: tlmm-key-default-state {
		pins = "gpio2", "gpio126", "gpio128", "gpio129", "gpio127";
		function = "gpio";
		drive-strength = <2>;
		input-enable;
		bias-pull-up;
	};

	wcd_default: wcd-reset-n-active-state {
		pins = "gpio107";
		function = "gpio";
		drive-strength = <16>;
		bias-disable;
		output-low;
	};
	
	fan0_pwr_active: fan0-pwr-active-state {
		pins = "gpio124","gpio125";
		function = "gpio";
		drive-strength = <2>;
		bias-disable;
		output-high;
	};

	fan0_int_active: fan0-int-active-state {
		pins = "gpio14";
		function = "gpio";
		drive-strength = <2>;
		bias-pull-pull;
		input-enable;
	};

	fan0_pwr_sleep: fan0-pwr-sleep-state {
		pins = "gpio124", "gpio125";
		function = "gpio";
		drive-strength = <2>;
		bias-disable;
		output-low;
	};

	usb_typec_pwr_en: usb-typec-vbus-en-state {
		pins = "gpio108", "gpio109";
		function = "gpio";
		drive-strength = <2>;
		bias-disable;
		output-high;
	};

	qup_uart13_default: qup-uart13-default-state {
		/* TX, RX */
		pins = "gpio22", "gpio23";
		function = "qup2_se5";
		drive-strength = <2>;
		bias-disable;
	};

	qup_uart13_sleep: qup-uart13-sleep-state {
		/* TX, RX */
		pins = "gpio22", "gpio23";
		function = "gpio";
		drive-strength = <2>;
		bias-pull-down;
	};
};


&pcie1 {
	vdda-supply = <&vph_pwr>;
	vddpe-3v3-supply = <&vph_pwr>; // XXX

	wake-gpios = <&tlmm 99 GPIO_ACTIVE_HIGH>;
	perst-gpios = <&tlmm 97 GPIO_ACTIVE_LOW>;

	pinctrl-0 = <&pcie1_default_state>,<&upd720201_active>, <&gamepad_pwr_en>;
	pinctrl-names = "default";

	status = "okay";
};

&pcie1_phy {
	vdda-phy-supply = <&vreg_l3e_0p9>;
	vdda-pll-supply = <&vreg_l3i_1p2>;
	vdda-qref-supply = <&vreg_l1i_0p88>;

	status = "okay";
};


&pm8550ve_gpios {
	gpio-line-names =
		// GPIO01 - GPIO08
		"",  "",  "",  "",  "",  "",  "",  "";
};

&spi0 {
	status = "okay";

	// Remove Hardware Chip Select
	pinctrl-0 = <&qup_spi0_data_clk>;

	fpga_cspi@0 {
		status = "okay";
		compatible = "linux,spidev";
		spi-max-frequency = <11000000>;
		reg = <0>;
	};
};

&tlmm {
	bt_default: bt-default-state {
		bt-en-pins {
			pins = "gpio17";
			function = "gpio";
			drive-strength = <16>;
			bias-disable;
		};

		sw-ctrl-pins {
			pins = "gpio18";
			function = "gpio";
			bias-pull-down;
		};
	};

	i2c5_default: i2c5-default-state {
		pins = "gpio52", "gpio53";
		function = "gpio";
		drive-strength = <2>;
		bias-pull-up;
	};

	wlan_en: wlan-en-state {
		pins = "gpio16";
		function = "gpio";
		drive-strength = <8>;
		bias-pull-down;
	};
};

&ufs_mem_hc {
	reset-gpios = <&tlmm 210 GPIO_ACTIVE_LOW>;

	vcc-supply = <&vreg_l17b_2p5>;
	vcc-max-microamp = <1300000>;
	vccq-supply = <&vreg_l1c_1p2>;
	vccq-max-microamp = <1200000>;

	status = "okay";
};

&ufs_mem_phy {
	vdda-phy-supply = <&vreg_l1d_0p9>;
	vdda-pll-supply = <&vreg_l3i_1p2>;

	status = "okay";
};

&usb_1 {
	dr_mode = "otg";
	usb-role-switch;
	status = "okay";
};

&usb_1_dwc3_hs {
	remote-endpoint = <&eud_ep>;
};

&eud {
	status = "okay";
	usb-role-switch;
};

&eud_con {
	remote-endpoint = <&pm8550b_role_switch_out>;
};

&eud_ep {
	remote-endpoint = <&usb_1_dwc3_hs>;
};

&usb_1_hsphy {
	vdd-supply = <&vreg_l1i_0p88>;
	vdda12-supply = <&vreg_l3i_1p2>;

	phys = <&pm8550b_eusb2_repeater>;

	status = "okay";
};

&usb_dp_qmpphy {
	vdda-phy-supply = <&vreg_l3i_1p2>;
	vdda-pll-supply = <&vreg_l3g_0p91>;

	orientation-switch;

	status = "okay";
};

&xo_board {
	clock-frequency = <76800000>;
};
